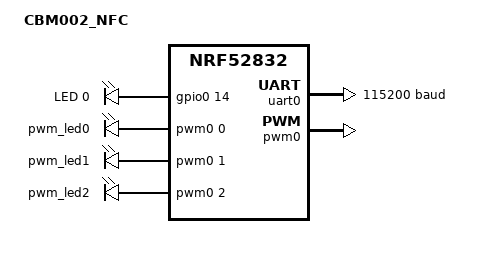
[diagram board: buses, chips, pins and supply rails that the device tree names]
// Copyright (c) 2023 Nordic Semiconductor ASA
// SPDX-License-Identifier: Apache-2.0

/dts-v1/;
#include <nordic/nrf52832_qfaa.dtsi>
#include "cbm002_nfc_pinctrl.dtsi"
/ {
	model = "CBM002_NFC";
	compatible = "casambi,cbm002-nfc";

	chosen {
		zephyr,console = &uart0;
		zephyr,sram = &sram0;
		zephyr,flash = &flash0;
		zephyr,code-partition = &slot0_partition;
	};
	leds {
		compatible = "gpio-leds";
		led0: led_0 {
			gpios = <&gpio0 14 GPIO_ACTIVE_HIGH>;
			label = "LED 0";
		};
	};

	pwmleds {
		compatible = "pwm-leds";
		pwm_led0: pwm_led_0 {
			pwms = <&pwm0 0 PWM_MSEC(1) PWM_POLARITY_NORMAL>;
		};
		pwm_led1: pwm_led_1 {
			pwms = <&pwm0 1 PWM_MSEC(1) PWM_POLARITY_NORMAL>;
		};
		pwm_led2: pwm_led_2 {
			pwms = <&pwm0 2 PWM_MSEC(1) PWM_POLARITY_NORMAL>;
		};

	};

	aliases {
		led0 = &led0;
		ledr = &pwm_led0;
		ledg = &pwm_led1;
		ledb = &pwm_led2;

	};
};


&gpio0 {
	status = "okay";
};

&uart0 {
	status = "okay";
	compatible = "nordic,nrf-uarte";
	current-speed = <115200>;
	pinctrl-0 = <&uart0_default>;
	pinctrl-1 = <&uart0_sleep>;
	pinctrl-names = "default", "sleep";
};



&pwm0 {
	status = "okay";
	pinctrl-0 = <&pwm0_default>;
	pinctrl-1 = <&pwm0_sleep>;
	pinctrl-names = "default", "sleep";
};

&flash0 {
	partitions {
		compatible = "fixed-partitions";
		#address-cells = <1>;
		#size-cells = <1>;

		boot_partition: partition@0 {
			label = "mcuboot";
			reg = <0x0 0xc000>;
		};
		slot0_partition: partition@c000 {
			label = "image-0";
			reg = <0xc000 0x64000>;
		};
		// slot1_partition: partition@3e000 {
			//     label = "image-1";
			//     reg = <0x3e000 0x32000>;
		// };
		scratch_partition: partition@70000 {
			label = "image-scratch";
			reg = <0x70000 0xa000>;
		};
		storage_partition: partition@7a000 {
			label = "storage";
			reg = <0x7a000 0x6000>;
		};
	};
};

